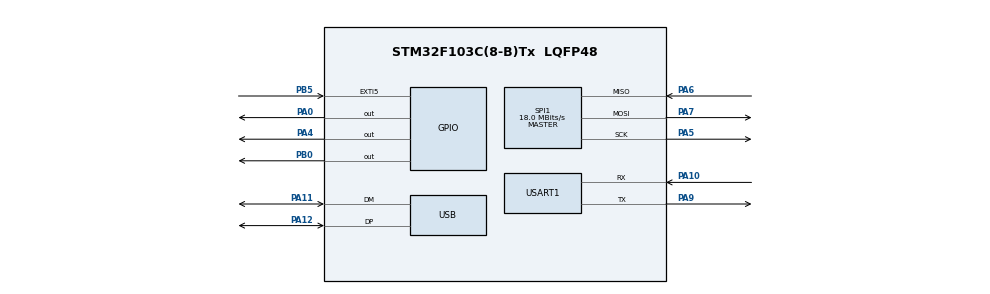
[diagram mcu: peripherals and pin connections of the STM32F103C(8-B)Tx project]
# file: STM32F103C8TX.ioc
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Dma.Request0=SPI1_RX
Dma.SPI1_RX.0.Direction=DMA_PERIPH_TO_MEMORY
Dma.SPI1_RX.0.Instance=DMA1_Channel2
Dma.SPI1_RX.0.MemDataAlignment=DMA_MDATAALIGN_BYTE
Dma.SPI1_RX.0.MemInc=DMA_MINC_ENABLE
Dma.SPI1_RX.0.Mode=DMA_CIRCULAR
Dma.SPI1_RX.0.PeriphDataAlignment=DMA_PDATAALIGN_BYTE
Dma.SPI1_RX.0.PeriphInc=DMA_PINC_DISABLE
Dma.SPI1_RX.0.Priority=DMA_PRIORITY_VERY_HIGH
Mcu.Family=STM32F1
Mcu.Name=STM32F103C(8-B)Tx
Mcu.Package=LQFP48
NVIC.DMA1_Channel2_IRQn=true\:0\:0\:false\:false\:true\:false\:true\:true
NVIC.EXTI9_5_IRQn=true\:0\:0\:false\:false\:true\:true\:true\:true
NVIC.PriorityGroup=NVIC_PRIORITYGROUP_4
NVIC.USB_LP_CAN1_RX0_IRQn=true\:0\:0\:false\:false\:true\:false\:true\:true
PA0-WKUP.GPIO_ModeDefaultOutputPP=GPIO_MODE_OUTPUT_OD
PA0-WKUP.GPIO_PuPd=GPIO_NOPULL
PA0-WKUP.GPIO_Speed=GPIO_SPEED_FREQ_HIGH
PA0-WKUP.PinState=GPIO_PIN_SET
PA0-WKUP.Signal=GPIO_Output
PA10.Mode=Asynchronous
PA10.Signal=USART1_RX
PA11.Mode=Device
PA11.Signal=USB_DM
PA12.Mode=Device
PA12.Signal=USB_DP
PA13.Mode=Serial_Wire
PA13.Signal=SYS_JTMS-SWDIO
PA14.Mode=Serial_Wire
PA14.Signal=SYS_JTCK-SWCLK
PA4.GPIO_Speed=GPIO_SPEED_FREQ_HIGH
PA4.PinState=GPIO_PIN_SET
PA4.Signal=GPIO_Output
PA5.Mode=Full_Duplex_Master
PA5.Signal=SPI1_SCK
PA6.Mode=Full_Duplex_Master
PA6.Signal=SPI1_MISO
PA7.Mode=Full_Duplex_Master
PA7.Signal=SPI1_MOSI
PA9.Mode=Asynchronous
PA9.Signal=USART1_TX
PB0.GPIO_Speed=GPIO_SPEED_FREQ_HIGH
PB0.Signal=GPIO_Output
PB5.GPIO_PuPd=GPIO_PULLDOWN
PB5.Signal=GPXTI5
PD0-OSC_IN.Mode=HSE-External-Oscillator
PD0-OSC_IN.Signal=RCC_OSC_IN
PD1-OSC_OUT.Mode=HSE-External-Oscillator
PD1-OSC_OUT.Signal=RCC_OSC_OUT
ProjectManager.HeapSize=0x200
ProjectManager.StackSize=0x400
ProjectManager.TargetToolchain=STM32CubeIDE
RCC.AHBFreq_Value=72000000
RCC.APB1CLKDivider=RCC_HCLK_DIV2
RCC.APB1Freq_Value=36000000
RCC.APB1TimFreq_Value=72000000
RCC.APB2Freq_Value=72000000
RCC.APB2TimFreq_Value=72000000
RCC.HCLKFreq_Value=72000000
RCC.PLLMUL=RCC_PLL_MUL9
RCC.PLLSourceVirtual=RCC_PLLSOURCE_HSE
RCC.SYSCLKFreq_VALUE=72000000
RCC.SYSCLKSource=RCC_SYSCLKSOURCE_PLLCLK
RCC.USBFreq_Value=48000000
RCC.USBPrescaler=RCC_USBCLKSOURCE_PLL_DIV1_5
SPI1.BaudRatePrescaler=SPI_BAUDRATEPRESCALER_4
SPI1.CalculateBaudRate=18.0 MBits/s
SPI1.Direction=SPI_DIRECTION_2LINES
SPI1.Mode=SPI_MODE_MASTER
SPI1.VirtualType=VM_MASTER
TIM1.AutoReloadPreload=TIM_AUTORELOAD_PRELOAD_ENABLE
TIM1.Prescaler=71
USART1.VirtualMode=VM_ASYNC
USB_DEVICE.CLASS_NAME_FS=CDC
USB_DEVICE.USBD_SELF_POWERED=1
USB_DEVICE.VirtualMode=Cdc
USB_DEVICE.VirtualModeFS=Cdc_FS
VP_TIM1_VS_ClockSourceINT.Mode=Internal
VP_USB_DEVICE_VS_USB_DEVICE_CDC_FS.Mode=CDC_FS
board=custom

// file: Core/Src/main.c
/* USER CODE BEGIN Header */
/**
 ******************************************************************************
 * @file           : main.c
 * @brief          : Main program body
 ******************************************************************************
 * @attention
 *
 * Copyright (c) 2025 STMicroelectronics.
 * All rights reserved.
 *
 * This software is licensed under terms that can be found in the LICENSE file
 * in the root directory of this software component.
 * If no LICENSE file comes with this software, it is provided AS-IS.
 *
 ******************************************************************************
 */
/* USER CODE END Header */
#include "main.h"
#include "dma.h"
#include "gpio.h"
#include "spi.h"
#include "tim.h"
#include "usart.h"
#include "usb_device.h"

/* USER CODE BEGIN Includes */

#include "apps.h"

/* USER CODE END Includes */

void SystemClock_Config(void);

int main(void)
{

    /* MCU Configuration--------------------------------------------------------*/

    /* Reset of all peripherals, Initializes the Flash interface and the Systick. */
    HAL_Init();

    /* Configure the system clock */
    SystemClock_Config();

    /* Initialize all configured peripherals */
    MX_GPIO_Init();
    MX_DMA_Init();
    MX_SPI1_Init();
    MX_USART1_UART_Init();
    MX_USB_DEVICE_Init();
    MX_TIM1_Init();
    /* USER CODE BEGIN 2 */

    apps_execution();

    /* USER CODE END 2 */

    /* Infinite loop */
    while (1)
    {

    }
}

void SystemClock_Config(void)
{
    LL_FLASH_SetLatency(LL_FLASH_LATENCY_2);
    while (LL_FLASH_GetLatency() != LL_FLASH_LATENCY_2)
    {
    }
    LL_RCC_HSE_Enable();

    /* Wait till HSE is ready */
    while (LL_RCC_HSE_IsReady() != 1)
    {
    }
    LL_RCC_PLL_ConfigDomain_SYS(LL_RCC_PLLSOURCE_HSE_DIV_1, LL_RCC_PLL_MUL_9);
    LL_RCC_PLL_Enable();

    /* Wait till PLL is ready */
    while (LL_RCC_PLL_IsReady() != 1)
    {
    }
    LL_RCC_SetAHBPrescaler(LL_RCC_SYSCLK_DIV_1);
    LL_RCC_SetAPB1Prescaler(LL_RCC_APB1_DIV_2);
    LL_RCC_SetAPB2Prescaler(LL_RCC_APB2_DIV_1);
    LL_RCC_SetSysClkSource(LL_RCC_SYS_CLKSOURCE_PLL);

    /* Wait till System clock is ready */
    while (LL_RCC_GetSysClkSource() != LL_RCC_SYS_CLKSOURCE_STATUS_PLL)
    {
    }
    LL_SetSystemCoreClock(72000000);

    /* Update the time base */
    if (HAL_InitTick(TICK_INT_PRIORITY) != HAL_OK)
    {
        Error_Handler();
    }
    LL_RCC_SetUSBClockSource(LL_RCC_USB_CLKSOURCE_PLL_DIV_1_5);
}

void Error_Handler(void)
{
    __disable_irq();
    while (1)
    {
    }
}
